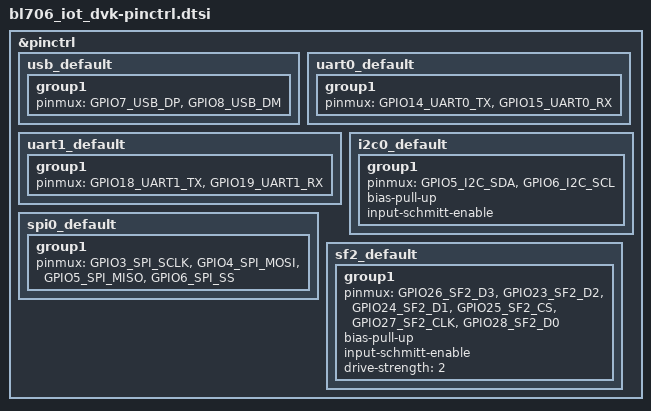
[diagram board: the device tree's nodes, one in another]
/*
 * SPDX-FileCopyrightText: Copyright The Zephyr Project Contributors
 * SPDX-License-Identifier: Apache-2.0
 */

&pinctrl {
	usb_default: usb_default {
		group1 {
			pinmux = <GPIO7_USB_DP>,
				 <GPIO8_USB_DM>;
		};
	};

	uart0_default: uart0_default {
		group1 {
			pinmux = <GPIO14_UART0_TX>,
				 <GPIO15_UART0_RX>;
		};
	};

	uart1_default: uart1_default {
		group1 {
			pinmux = <GPIO18_UART1_TX>,
				 <GPIO19_UART1_RX>;
		};
	};

	i2c0_default: i2c0_default {
		group1 {
			pinmux = <GPIO5_I2C_SDA>,
				 <GPIO6_I2C_SCL>;
			bias-pull-up;
			input-schmitt-enable;
		};
	};

	spi0_default: spi0_default {
		group1 {
			pinmux = <GPIO3_SPI_SCLK>,
				 <GPIO4_SPI_MOSI>,
				 <GPIO5_SPI_MISO>,
				 <GPIO6_SPI_SS>;
		};
	};

	sf2_default: sf2_default {
		group1 {
			pinmux = <GPIO26_SF2_D3>,
				 <GPIO23_SF2_D2>,
				 <GPIO24_SF2_D1>,
				 <GPIO25_SF2_CS>,
				 <GPIO27_SF2_CLK>,
				 <GPIO28_SF2_D0>;
			bias-pull-up;
			input-schmitt-enable;
			drive-strength = <2>;
		};
	};
};
